# C6424_cslr_emif register map
Vendor: Texas Instruments
Peripheral module from a debugger description file.
Registers are 32-bit, access not given, reset 0x0 unless marked. A register's access mark holds for its fields unless they carry their own. Offsets are as the file gives them; lines under a group give offsets from that group; [hi:lo] are bit positions; {n}, {i} and the like mark numbered series; 'fields as' and 'values as' point back to an identical list; <NAME> marks a mode.

## EMIF — External Memory Interface
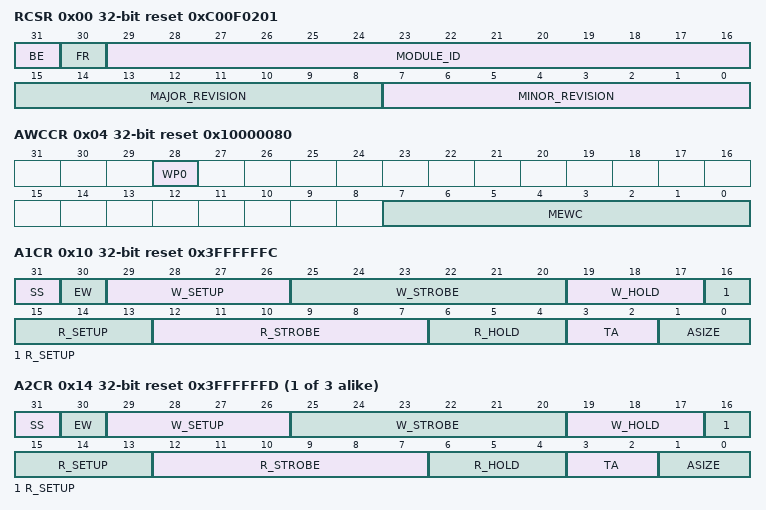
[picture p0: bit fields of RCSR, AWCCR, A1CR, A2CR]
0x00 RCSR ro reset 0xC00F0201 — This register reflects the revision code of the module.
  [31] BE — Big Endian. Reflects whether the EMIF is in big-endian or little-endian mode.
    0=LITTLE (Little-endian mode); 1=BIG (Big-endian mode)
  [30] FR — Full Rate. Reflects whether the EMIF is set to operate at full or half rate.
    0=HALFRATE (Operating in Half Rate); 1=FULLRATE (Operating in Full Rate)
  [29:16] MODULE_ID — Module identification. EMIF: Fh = asynchronous mode
  [15:8] MAJOR_REVISION — Major Revision. EMIF code revisions are indicated by a revision code taking the format MAJOR_REVISION.MINOR_REVISION.
  [7:0] MINOR_REVISION — Minor Revision. EMIF code revisions are indicated by a revision code taking the format MAJOR_REVISION.MINOR_REVISION.
0x04 AWCCR reset 0x10000080 — Asynchronous Wait Cycle Configuration Register
  [28] WP0 rw — WAIT polarity bit. This bit defines the polarity of the EM_WAIT pin. 0: Insert wait cycles if EM_WAIT is low. 1: Insert wait cycles if EM_WAIT is high.
    0=WAITLOW (Insert wait cycles if EM_WAIT is low); 1=WAITHIGH (Insert wait cycles if EM_WAIT is high.)
  [7:0] MEWC rw — Maximum External Wait Cycles The EMIF will wait for (MEWC + 1)*16 clock cycles before an extended asynchronous cycle is terminated.
0x10 A1CR rw reset 0x3FFFFFFC — Asynchronous Bank 1 Configuration Register
  [31] SS — Select Strobe bit. This bit defines whether the asynchronous interface operates in Normal mode or Select Strobe mode. Set to 1select Strobe mode is enabled.
  [30] EW — Extend Wait bit. This bit defines whether extended wait cycles will be enabled. This bit field must be cleared to 0, if the EMIF on your device does not have a EM_WAIT pin.
  [29:26] W_SETUP — WritWrite setup width in EMIF clock cycles, minus 1 cycle.
  [25:20] W_STROBE — Write strobe width in EMIF clock cycles, minus 1 cycle.
  [19:17] W_HOLD — Write hold width in EMIF clock cycles, minus 1 cycle.
  [16:13] R_SETUP — Read setup width in EMIF clock cycles, minus 1 cycle.
  [12:7] R_STROBE — Read strobe width in EMIF clock cycles, minus 1 cycle.
  [6:4] R_HOLD — Read hold width in EMIF clock cycles, minus 1 cycle.
  [3:2] TA — Turn around cycles Minimum Turn-Around time. This field defines the minimum number of EMIF clock cycles between the end of one asynchronous access and the start of another, minus 1 cycle. This delay is not incurred by a read followed by a read or a write followed by a write to the same CS space.
  [1:0] ASIZE — Asynchronous data bus width. This bit defines the width of the asynchronous device's data bus.
    0=ASIZE_8BITS (8-bit data bus); 1=ASIZE_16BITS (16-bit data bus)
{0xC+4i} A{i}CR rw reset 0x3FFFFFFD (i=2..4) — Asynchronous Bank {i} Configuration Register
  fields as A1CR
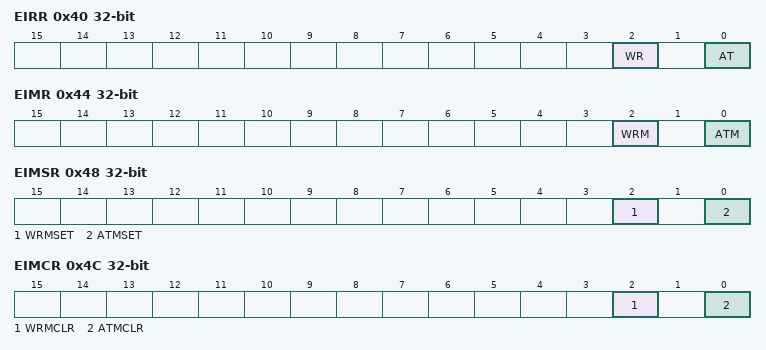
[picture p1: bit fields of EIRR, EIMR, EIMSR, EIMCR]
0x40 EIRR — EMIF Interrupt Raw Register
  [2] WR rw — Wait Rise. This bit is set to 1 by hardware to indicate that a rising edge on the EM_WAIT pin has occurred.
  [0] AT rw — Asynchronous Timeout This bit is set to 1 by hardware to indicate that during an extended asynchronous memory access cycle the EM_WAIT pin did not go inactive within the number of cycles defined by the MEWC field in the asynchronous wait cycle configuration register (AWCCR).
0x44 EIMR — EMIF Interrupt Mask Register
  [2] WRM rw — Wait Rise Masked. This bit is set to 1 by hardware to indicate a rising edge has occurred on the EM_WAIT pin, provided that the WRMSET bit is set to 1 in the EMIF interrupt mask set register (EIMSR).
  [0] ATM rw — Asynchronous Timeout Masked. This bit is set to 1 by hardware to indicate that during an extended asynchronous memory access cycle the EM_WAIT pin did not go inactive within the number of cycles defined by the MEWC field in the asynchronous wait cycle configuration register (AWCCR), provided that the ATMSET bit is set to 1 in the EMIF interrupt mask set register (EIMSR).
0x48 EIMSR — EMIF Interrupt Mask Set Register
  [2] WRMSET rw — Wait Rise Mask Set. This bit determines whether or not the wait rise Interrupt is enabled. Writing a 1 to this bit sets this bit, sets the WRMCLR bit in the EMIF interrupt mask clear register (EIMCR), and enables the wait rise interrupt. To clear this bit, a 1 must be written to the WRMCLR bit in EIMCR.
  [0] ATMSET rw — Asynchronous Timeout Mask Set. This bit determines whether or not the asynchronous timeout interrupt is enabled. Writing a 1 to this bit sets this bit, sets the ATMCLR bit in the EMIF interrupt mask clear register (EIMCR), and enables the asynchronous timeout interrupt. To clear this bit, a 1 must be written to the ATMCLR bit in EIMCR.
0x4C EIMCR — EMIF Interrupt Mask Clear Register
  [2] WRMCLR rw — Wait Rise Mask Clear. This bit determines whether or not the wait rise interrupt is enabled. Writing a 1 to this bit clears this bit, clears the WRMSET bit in the EMIF interrupt mask set register (EIMSR), and disables the wait rise interrupt. To set this bit, a 1 must be written to the WRMSET bit in EIMSR.
  [0] ATMCLR rw — Asynchronous Timeout Mask Clear. This bit determines whether or not the asynchronous timeout interrupt is enabled. Writing a 1 to this bit clears this bit, clears the ATMSET bit in the EMIF interrupt mask set register (EIMSR), and disables the asynchronous timeout interrupt. To set this bit, a 1 must be written to the ATMSET bit in EIMSR.
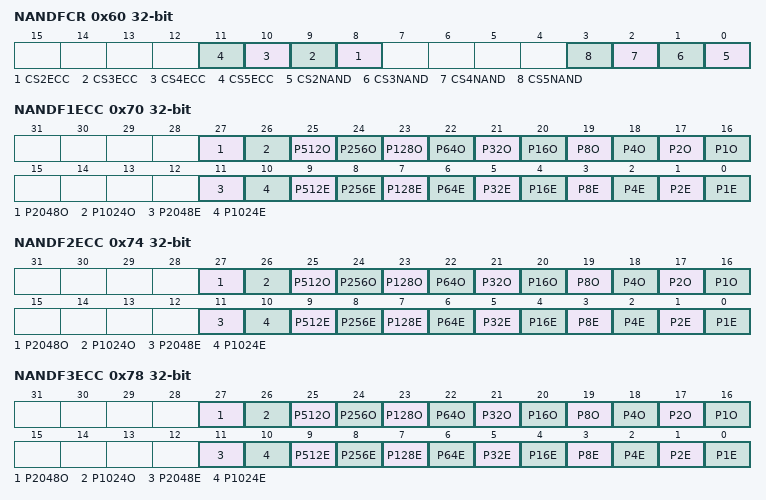
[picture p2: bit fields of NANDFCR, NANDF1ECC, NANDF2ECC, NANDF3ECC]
0x60 NANDFCR — NAND Flash Control Register
  [n+6] CS{n}ECC rw (n=2..5) — NAND Flash ECC start for chip select {n}. Set to 1 to start ECC calculation on data for NAND Flash on EM_CS[{n}]
  [n-2] CS{n}NAND rw (n=2..5) — NAND Flash mode for chip select {n}. Set to 1 if using NAND Flash on EM_CS[{n}]
0x64 NANDFSR — NAND Flash Status Register
  [3:0] WAITST ro — Raw status of the EM_WAIT input pin. The WP0 bit in the asynchronous wait cycle configuration register (AWCCR) has no effect on WAITST.
0x70 NANDF1ECC — NAND Flash 1 ECC Register
  [27] P2048O ro — ECC code calculated while reading/writing NAND Flash. For 8-bit NAND Flash, p1o, p2o, and p4o are column parities. p8o to p2048o are row parities. For 16-bit NAND Flash, p1o, p2o, p4o and p8o are column parities. p16o to p2048o are row parities.
  [26] P1024O ro
  [25] P512O ro
  [24] P256O ro
  [23] P128O ro
  [22] P64O ro
  [21] P32O ro
  [20] P16O ro
  [19] P8O ro
  [18] P4O ro
  [17] P2O ro
  [16] P1O ro
  [11] P2048E ro — ECC code calculated while reading/writing NAND Flash. For 8-bit NAND Flash, p1o, p2o, and p4o are column parities. p8o to p2048o are row parities. For 16-bit NAND Flash, p1o, p2o, p4o and p8o are column parities. p16o to p2048o are row parities.
  [10] P1024E ro
  [9] P512E ro
  [8] P256E ro
  [7] P128E ro
  [6] P64E ro
  [5] P32E ro
  [4] P16E ro
  [3] P8E ro
  [2] P4E ro
  [1] P2E ro
  [0] P1E ro
0x74 NANDF2ECC — NAND Flash 2 ECC Register
  [27] P2048O ro — ECC code calculated while reading/writing NAND Flash. For 8-bit NAND Flash, p1o, p2o, and p4o are column parities. p8o to p2048o are row parities For 16-bit NAND Flash, p1o, p2o, p4o and p8o are column parities. p16o to p2048o are row parities.
  [26] P1024O ro
  [25] P512O ro
  [24] P256O ro
  [23] P128O ro
  [22] P64O ro
  [21] P32O ro
  [20] P16O ro
  [19] P8O ro
  [18] P4O ro
  [17] P2O ro
  [16] P1O ro
  [11] P2048E ro — ECC code calculated while reading/writing NAND Flash. For 8-bit NAND Flash, p1o, p2o, and p4o are column parities. p8o to p2048o are row parities. For 16-bit NAND Flash, p1o, p2o, p4o and p8o are column parities. p16o to p2048o are row parities.
  [10] P1024E ro
  [9] P512E ro
  [8] P256E ro
  [7] P128E ro
  [6] P64E ro
  [5] P32E ro
  [4] P16E ro
  [3] P8E ro
  [2] P4E ro
  [1] P2E ro
  [0] P1E ro
0x78 NANDF3ECC — NAND Flash 3 ECC Register
  fields as NANDF1ECC
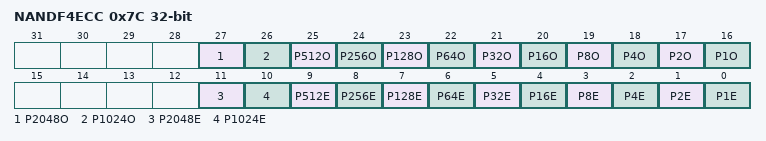
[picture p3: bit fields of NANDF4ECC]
0x7C NANDF4ECC — NAND Flash 4 ECC Register
  fields as NANDF1ECC
